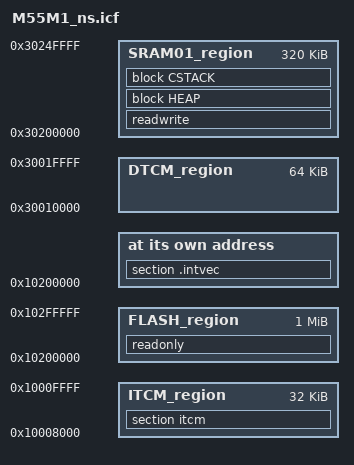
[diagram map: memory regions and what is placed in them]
/*###ICF### Section handled by ICF editor, don't touch! ****/
/*-Editor annotation file-*/
/* IcfEditorFile="$TOOLKIT_DIR$\config\ide\IcfEditor\cortex_v1_0.xml" */
/*-Specials-*/
define symbol __ICFEDIT_intvec_start__ = 0x10200000;
/*-Memory Regions-*/
define symbol __ICFEDIT_region_ITCM_start__   = 0x10008000;
define symbol __ICFEDIT_region_ITCM_end__     = 0x1000FFFF;
define symbol __ICFEDIT_region_FLASH_start__  = 0x10200000;
define symbol __ICFEDIT_region_FLASH_end__    = 0x102FFFFF;
define symbol __ICFEDIT_region_SRAM01_start__ = 0x30200000;
define symbol __ICFEDIT_region_SRAM01_end__   = 0x3024FFFF;
define symbol __ICFEDIT_region_DTCM_start__   = 0x30010000;
define symbol __ICFEDIT_region_DTCM_end__     = 0x3001FFFF;

/*-Sizes-*/
define symbol __ICFEDIT_size_cstack__ = 0x00008000;
define symbol __ICFEDIT_size_heap__   = 0x00010000;
/**** End of ICF editor section. ###ICF###*/


define memory mem with size = 4G;
define region ITCM_region   = mem:[from __ICFEDIT_region_ITCM_start__   to __ICFEDIT_region_ITCM_end__];
define region FLASH_region   = mem:[from __ICFEDIT_region_FLASH_start__   to __ICFEDIT_region_FLASH_end__];
define region SRAM01_region   = mem:[from __ICFEDIT_region_SRAM01_start__   to __ICFEDIT_region_SRAM01_end__];
define region DTCM_region   = mem:[from __ICFEDIT_region_DTCM_start__   to __ICFEDIT_region_DTCM_end__];

define block CSTACK    with alignment = 8, size = __ICFEDIT_size_cstack__   { };
define block HEAP      with alignment = 8, size = __ICFEDIT_size_heap__     { };

initialize by copy { readwrite, section itcm };

do not initialize  { section .noinit, section .bss.tensor_arena, section .bss.NoInit.activation_buf_sram };

place at address mem:__ICFEDIT_intvec_start__ { section .intvec };

place in FLASH_region   { readonly}
                        except {section itcm};
place in ITCM_region   { section itcm };
/*place in DTCM_region   { block CSTACK, block HEAP };*/
place in SRAM01_region   { readwrite, block HEAP, block CSTACK };

